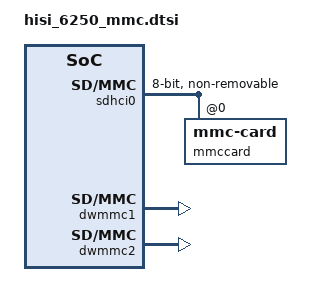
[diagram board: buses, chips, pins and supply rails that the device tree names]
/{
	aliases {
		mshc1 = &dwmmc1;
		mshc2 = &dwmmc2;
	};

	/* emmc 5.0 */
	sdhci0: sdhci@FF390000 {
		compatible = "arasan,sdhci";
		reg = <0x0 0xff390000 0x0 0x10000>;
		clock-names = "clk_xin", "clk_ahb";
		clocks = <&clk_gate_emmc0>, <&hclk_gate_emmc0>;
		interrupt-parent = <&gic>;
		interrupts = <0 137 4>;
		bus-width = <8>;
		non-removable;
		use-adma;//use-pio, use-dma, use-adma
		cmdq_check_busy;
		caps2-mmc-cache-ctrl;
		caps2-mmc-HC-erase-size;
		phy-config = <0x0 0x5>;
		peri-crg-rst-emmc0-bit = <16>;
		/*0--50ohm,1--33ohm,0x2--66ohm,3--100ohm,4--40ohm*/
		drv-strength = <4 4>;/*first:host drv-strength,second:dev drv-strength*/
		status = "ok";

		mmccard: mmccard@0 {
			reg = <0>;
			compatible = "mmc-card";
			broken-hpi;
		};
	};

	/* SD */
	dwmmc1: dwmmc1@FF37F000 {
		compatible = "hisilicon,hi6250-dw-mshc";
		reg = <0x0 0xff37f000 0x0 0x1000>;
		interrupts = <0 139 4>;
		num-slots = <1>;
		clocks = <&clk_gate_sd>, <&hclk_gate_sd>;
		clock-names = "ciu", "biu";
		fifo-depth = <0x100>;
		card-detect-delay = <200>;
		supports-highspeed;
		pinctrl-names = "default","idle";
		pinctrl-0 = <&gpio041_cfg_func &gpio042_cfg_func &gpio043_cfg_func
				&gpio044_cfg_func &gpio045_cfg_func &gpio046_cfg_func
				&gpio041_pmx_func &gpio042_pmx_func &gpio043_pmx_func
				&gpio044_pmx_func &gpio045_pmx_func &gpio046_pmx_func>;
		pinctrl-1 = <&gpio041_cfg_idle &gpio042_cfg_idle &gpio043_cfg_idle
				&gpio044_cfg_idle &gpio045_cfg_idle &gpio046_cfg_idle
				&gpio041_pmx_idle &gpio042_pmx_idle &gpio043_pmx_idle
				&gpio044_pmx_idle &gpio045_pmx_idle &gpio046_pmx_idle>;
		slot@0 {
                       reg = <0>;
                       bus-width = <4>;
                       disable-wp;
               };
	};

	/* wifi */
	dwmmc2: dwmmc2@ff37d000 {
		compatible = "hisilicon,hi6250-dw-mshc";
		reg = <0x0 0xff37d000 0x0 0x1000>;
		interrupts = <0 140 4>;
		num-slots = <1>;
		clocks = <&clk_gate_sdio0>, <&hclk_gate_sdio0>;
		clock-names = "ciu", "biu";
		fifo-depth = <0x100>;
		card-detect-delay = <200>;
		caps2-support-wifi;
		supports-highspeed;
		keep-power-in-suspend;
                pinctrl-names = "default","idle";
		pinctrl-0 = <>;
		pinctrl-1 = <>;
		slot@0 {
                       reg = <0>;
                       bus-width = <4>;
                       disable-wp;
               };
	};
};
